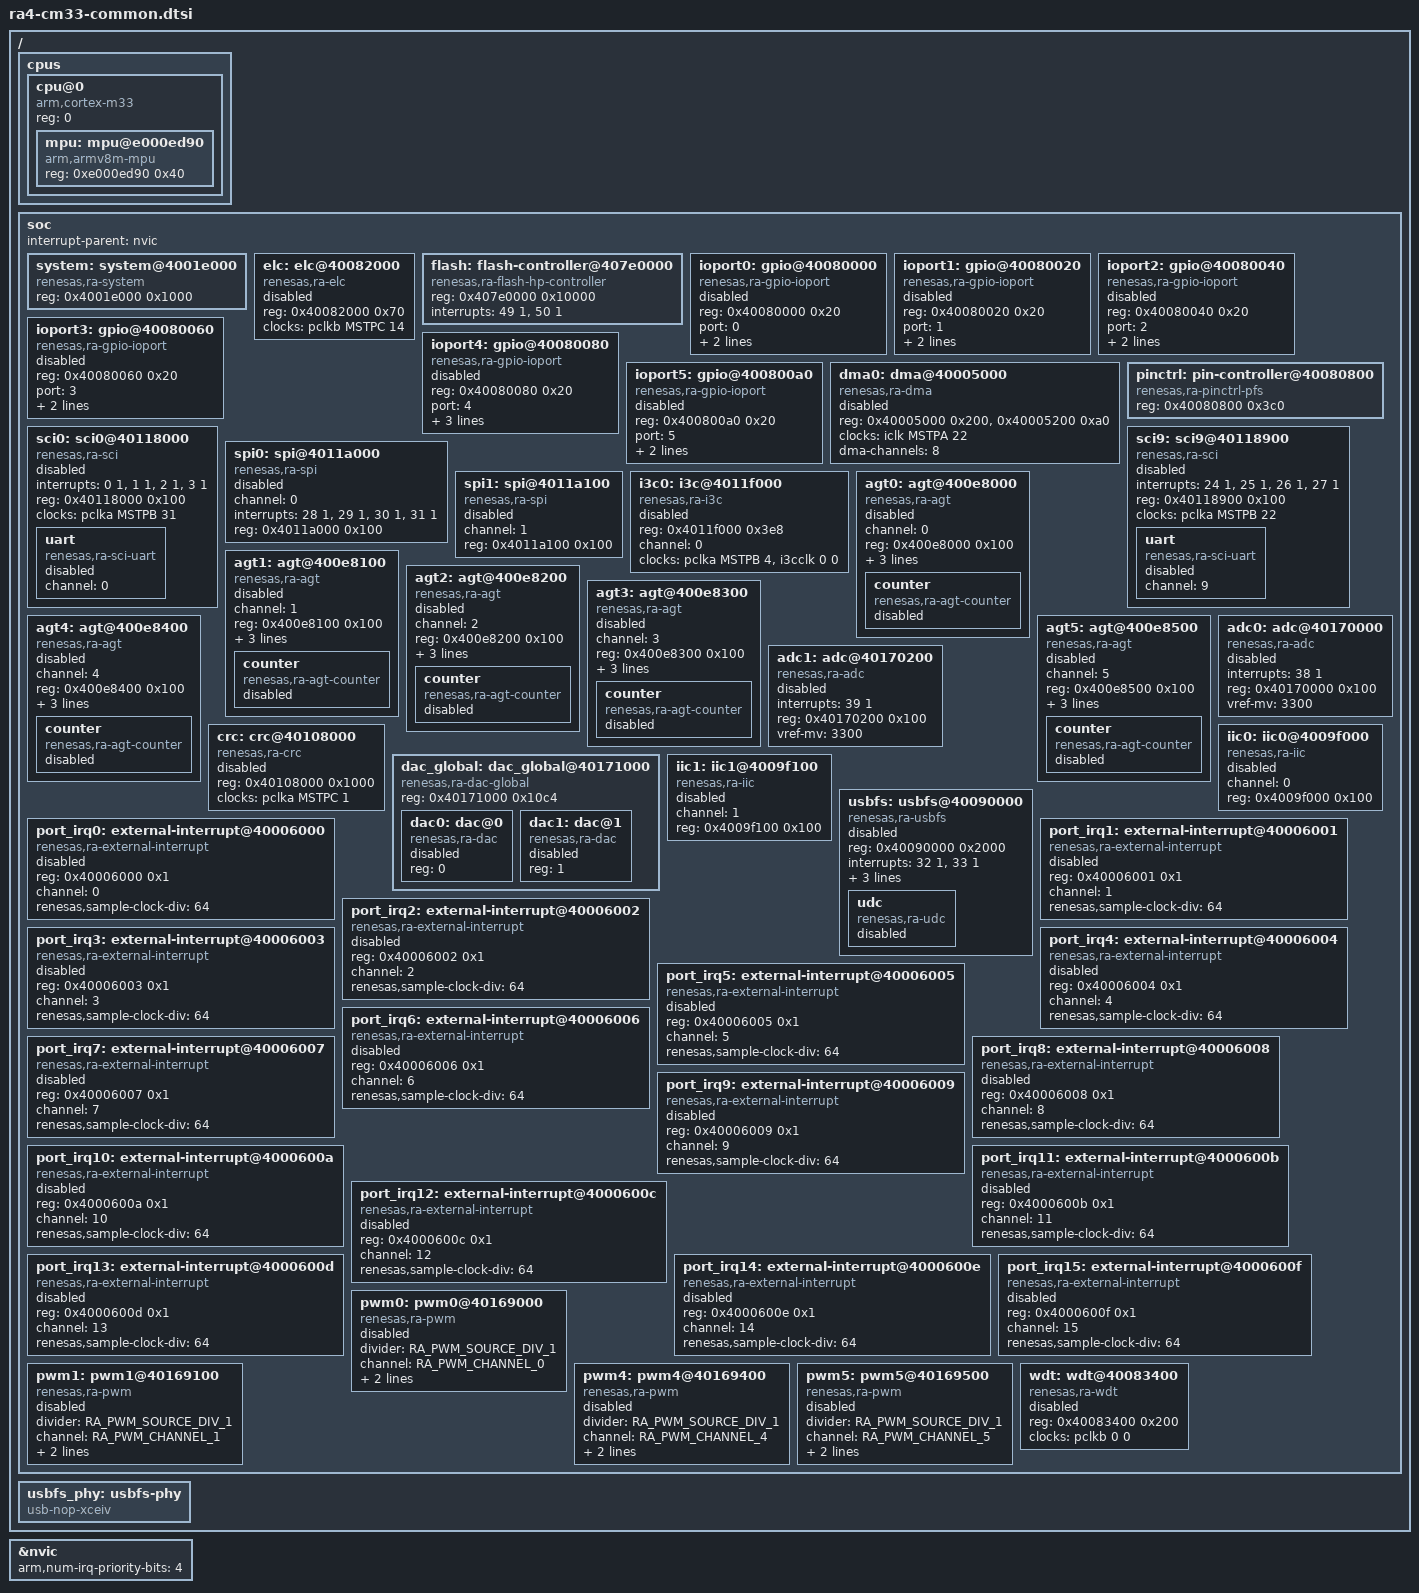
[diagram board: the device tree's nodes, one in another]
/*
 * Copyright (c) 2024-2025 Renesas Electronics Corporation
 *
 * SPDX-License-Identifier: Apache-2.0
 */

#include <mem.h>
#include <arm/armv8-m.dtsi>
#include <zephyr/dt-bindings/pinctrl/renesas/pinctrl-ra.h>
#include <zephyr/dt-bindings/pwm/ra_pwm.h>
#include <freq.h>

/ {
	cpus {
		#address-cells = <1>;
		#size-cells = <0>;

		cpu@0 {
			device_type = "cpu";
			compatible = "arm,cortex-m33";
			reg = <0>;
			#address-cells = <1>;
			#size-cells = <1>;

			mpu: mpu@e000ed90 {
				compatible = "arm,armv8m-mpu";
				reg = <0xe000ed90 0x40>;
			};
		};
	};

	soc {
		interrupt-parent = <&nvic>;

		system: system@4001e000 {
			compatible = "renesas,ra-system";
			reg = <0x4001e000 0x1000>;
			status = "okay";
		};

		elc: elc@40082000 {
			compatible = "renesas,ra-elc";
			reg = <0x40082000 0x70>;
			#renesas-elc-cells = <2>;
			clocks = <&pclkb MSTPC 14>;
			status = "disabled";
		};

		flash: flash-controller@407e0000 {
			compatible = "renesas,ra-flash-hp-controller";
			reg = <0x407e0000 0x10000>;
			#address-cells = <1>;
			#size-cells = <1>;
			interrupts = <49 1>, <50 1>;
			interrupt-names = "frdyi", "fiferr";
		};

		ioport0: gpio@40080000 {
			compatible = "renesas,ra-gpio-ioport";
			reg = <0x40080000 0x20>;
			port = <0>;
			gpio-controller;
			#gpio-cells = <2>;
			ngpios = <16>;
			status = "disabled";
		};

		ioport1: gpio@40080020 {
			compatible = "renesas,ra-gpio-ioport";
			reg = <0x40080020 0x20>;
			port = <1>;
			gpio-controller;
			#gpio-cells = <2>;
			ngpios = <16>;
			status = "disabled";
		};

		ioport2: gpio@40080040 {
			compatible = "renesas,ra-gpio-ioport";
			reg = <0x40080040 0x20>;
			port = <2>;
			gpio-controller;
			#gpio-cells = <2>;
			ngpios = <16>;
			status = "disabled";
		};

		ioport3: gpio@40080060 {
			compatible = "renesas,ra-gpio-ioport";
			reg = <0x40080060 0x20>;
			port = <3>;
			gpio-controller;
			#gpio-cells = <2>;
			ngpios = <16>;
			status = "disabled";
		};

		ioport4: gpio@40080080 {
			compatible = "renesas,ra-gpio-ioport";
			reg = <0x40080080 0x20>;
			port = <4>;
			gpio-controller;
			#gpio-cells = <2>;
			ngpios = <16>;
			vbatts-pins = <2 3 4>;
			status = "disabled";
		};

		ioport5: gpio@400800a0 {
			compatible = "renesas,ra-gpio-ioport";
			reg = <0x400800a0 0x20>;
			port = <5>;
			gpio-controller;
			#gpio-cells = <2>;
			ngpios = <16>;
			status = "disabled";
		};

		dma0: dma@40005000 {
			compatible = "renesas,ra-dma";
			reg = <0x40005000 0x200>, <0x40005200 0xa0>;
			reg-names = "channel", "common";
			clocks = <&iclk MSTPA 22>;
			dma-channels = <8>;
			#dma-cells = <2>;
			status = "disabled";
		};

		pinctrl: pin-controller@40080800 {
			compatible = "renesas,ra-pinctrl-pfs";
			reg = <0x40080800 0x3c0>;
			status = "okay";
		};

		sci0: sci0@40118000 {
			compatible = "renesas,ra-sci";
			interrupts = <0 1>, <1 1>, <2 1>, <3 1>;
			interrupt-names = "rxi", "txi", "tei", "eri";
			reg = <0x40118000 0x100>;
			clocks = <&pclka MSTPB 31>;
			status = "disabled";

			uart {
				compatible = "renesas,ra-sci-uart";
				channel = <0>;
				status = "disabled";
			};
		};

		sci9: sci9@40118900 {
			compatible = "renesas,ra-sci";
			interrupts = <24 1>, <25 1>, <26 1>, <27 1>;
			interrupt-names = "rxi", "txi", "tei", "eri";
			reg = <0x40118900 0x100>;
			clocks = <&pclka MSTPB 22>;
			status = "disabled";

			uart {
				compatible = "renesas,ra-sci-uart";
				channel = <9>;
				status = "disabled";
			};
		};

		spi0: spi@4011a000 {
			compatible = "renesas,ra-spi";
			#address-cells = <1>;
			#size-cells = <0>;
			channel = <0>;
			interrupts = <28 1>, <29 1>, <30 1>, <31 1>;
			interrupt-names = "rxi", "txi", "tei", "eri";
			reg = <0x4011a000 0x100>;
			status = "disabled";
		};

		spi1: spi@4011a100 {
			compatible = "renesas,ra-spi";
			#address-cells = <1>;
			#size-cells = <0>;
			channel = <1>;
			reg = <0x4011a100 0x100>;
			status = "disabled";
		};

		i3c0: i3c@4011f000 {
			compatible = "renesas,ra-i3c";
			#address-cells = <3>;
			#size-cells = <0>;
			reg = <0x4011f000 0x3e8>;
			channel = <0>;
			clocks = <&pclka MSTPB 4>, <&i3cclk 0 0>;
			clock-names = "pclk", "tclk";
			status = "disabled";
		};

		agt0: agt@400e8000 {
			compatible = "renesas,ra-agt";
			channel = <0>;
			reg = <0x400e8000 0x100>;
			renesas,count-source = "AGT_CLOCK_LOCO";
			renesas,prescaler = <0>;
			renesas,resolution = <16>;
			status = "disabled";

			counter {
				compatible = "renesas,ra-agt-counter";
				status = "disabled";
			};
		};

		agt1: agt@400e8100 {
			compatible = "renesas,ra-agt";
			channel = <1>;
			reg = <0x400e8100 0x100>;
			renesas,count-source = "AGT_CLOCK_LOCO";
			renesas,prescaler = <0>;
			renesas,resolution = <16>;
			status = "disabled";

			counter {
				compatible = "renesas,ra-agt-counter";
				status = "disabled";
			};
		};

		agt2: agt@400e8200 {
			compatible = "renesas,ra-agt";
			channel = <2>;
			reg = <0x400e8200 0x100>;
			renesas,count-source = "AGT_CLOCK_LOCO";
			renesas,prescaler = <0>;
			renesas,resolution = <16>;
			status = "disabled";

			counter {
				compatible = "renesas,ra-agt-counter";
				status = "disabled";
			};
		};

		agt3: agt@400e8300 {
			compatible = "renesas,ra-agt";
			channel = <3>;
			reg = <0x400e8300 0x100>;
			renesas,count-source = "AGT_CLOCK_LOCO";
			renesas,prescaler = <0>;
			renesas,resolution = <16>;
			status = "disabled";

			counter {
				compatible = "renesas,ra-agt-counter";
				status = "disabled";
			};
		};

		agt4: agt@400e8400 {
			compatible = "renesas,ra-agt";
			channel = <4>;
			reg = <0x400e8400 0x100>;
			renesas,count-source = "AGT_CLOCK_LOCO";
			renesas,prescaler = <0>;
			renesas,resolution = <16>;
			status = "disabled";

			counter {
				compatible = "renesas,ra-agt-counter";
				status = "disabled";
			};
		};

		agt5: agt@400e8500 {
			compatible = "renesas,ra-agt";
			channel = <5>;
			reg = <0x400e8500 0x100>;
			renesas,count-source = "AGT_CLOCK_LOCO";
			renesas,prescaler = <0>;
			renesas,resolution = <16>;
			status = "disabled";

			counter {
				compatible = "renesas,ra-agt-counter";
				status = "disabled";
			};
		};

		adc0: adc@40170000 {
			compatible = "renesas,ra-adc";
			interrupts = <38 1>;
			interrupt-names = "scanend";
			reg = <0x40170000 0x100>;
			#io-channel-cells = <1>;
			vref-mv = <3300>;
			status = "disabled";
		};

		adc1: adc@40170200 {
			compatible = "renesas,ra-adc";
			interrupts = <39 1>;
			interrupt-names = "scanend";
			reg = <0x40170200 0x100>;
			#io-channel-cells = <1>;
			vref-mv = <3300>;
			status = "disabled";
		};

		crc: crc@40108000 {
			compatible = "renesas,ra-crc";
			reg = <0x40108000 0x1000>;
			clocks = <&pclka MSTPC 1>;
			status = "disabled";
		};

		dac_global: dac_global@40171000 {
			compatible = "renesas,ra-dac-global";
			reg = <0x40171000 0x10c4>;
			#address-cells = <1>;
			#size-cells = <0>;

			dac0: dac@0 {
				compatible = "renesas,ra-dac";
				#io-channel-cells = <1>;
				reg = <0>;
				status = "disabled";
			};

			dac1: dac@1 {
				compatible = "renesas,ra-dac";
				#io-channel-cells = <1>;
				reg = <1>;
				status = "disabled";
			};
		};

		iic0: iic0@4009f000 {
			compatible = "renesas,ra-iic";
			channel = <0>;
			reg = <0x4009f000 0x100>;
			status = "disabled";
		};

		iic1: iic1@4009f100 {
			compatible = "renesas,ra-iic";
			channel = <1>;
			reg = <0x4009f100 0x100>;
			status = "disabled";
		};

		usbfs: usbfs@40090000 {
			compatible = "renesas,ra-usbfs";
			reg = <0x40090000 0x2000>;
			interrupts = <32 1>, <33 1>;
			interrupt-names = "usbfs-i", "usbfs-r";
			num-bidir-endpoints = <10>;
			phys = <&usbfs_phy>;
			phys-clock = <&uclk>;
			status = "disabled";

			udc {
				compatible = "renesas,ra-udc";
				status = "disabled";
			};
		};

		port_irq0: external-interrupt@40006000 {
			compatible = "renesas,ra-external-interrupt";
			reg = <0x40006000 0x1>;
			channel = <0>;
			renesas,sample-clock-div = <64>;
			#port-irq-cells = <0>;
			status = "disabled";
		};

		port_irq1: external-interrupt@40006001 {
			compatible = "renesas,ra-external-interrupt";
			reg = <0x40006001 0x1>;
			channel = <1>;
			renesas,sample-clock-div = <64>;
			#port-irq-cells = <0>;
			status = "disabled";
		};

		port_irq2: external-interrupt@40006002 {
			compatible = "renesas,ra-external-interrupt";
			reg = <0x40006002 0x1>;
			channel = <2>;
			renesas,sample-clock-div = <64>;
			#port-irq-cells = <0>;
			status = "disabled";
		};

		port_irq3: external-interrupt@40006003 {
			compatible = "renesas,ra-external-interrupt";
			reg = <0x40006003 0x1>;
			channel = <3>;
			renesas,sample-clock-div = <64>;
			#port-irq-cells = <0>;
			status = "disabled";
		};

		port_irq4: external-interrupt@40006004 {
			compatible = "renesas,ra-external-interrupt";
			reg = <0x40006004 0x1>;
			channel = <4>;
			renesas,sample-clock-div = <64>;
			#port-irq-cells = <0>;
			status = "disabled";
		};

		port_irq5: external-interrupt@40006005 {
			compatible = "renesas,ra-external-interrupt";
			reg = <0x40006005 0x1>;
			channel = <5>;
			renesas,sample-clock-div = <64>;
			#port-irq-cells = <0>;
			status = "disabled";
		};

		port_irq6: external-interrupt@40006006 {
			compatible = "renesas,ra-external-interrupt";
			reg = <0x40006006 0x1>;
			channel = <6>;
			renesas,sample-clock-div = <64>;
			#port-irq-cells = <0>;
			status = "disabled";
		};

		port_irq7: external-interrupt@40006007 {
			compatible = "renesas,ra-external-interrupt";
			reg = <0x40006007 0x1>;
			channel = <7>;
			renesas,sample-clock-div = <64>;
			#port-irq-cells = <0>;
			status = "disabled";
		};

		port_irq8: external-interrupt@40006008 {
			compatible = "renesas,ra-external-interrupt";
			reg = <0x40006008 0x1>;
			channel = <8>;
			renesas,sample-clock-div = <64>;
			#port-irq-cells = <0>;
			status = "disabled";
		};

		port_irq9: external-interrupt@40006009 {
			compatible = "renesas,ra-external-interrupt";
			reg = <0x40006009 0x1>;
			channel = <9>;
			renesas,sample-clock-div = <64>;
			#port-irq-cells = <0>;
			status = "disabled";
		};

		port_irq10: external-interrupt@4000600a {
			compatible = "renesas,ra-external-interrupt";
			reg = <0x4000600a 0x1>;
			channel = <10>;
			renesas,sample-clock-div = <64>;
			#port-irq-cells = <0>;
			status = "disabled";
		};

		port_irq11: external-interrupt@4000600b {
			compatible = "renesas,ra-external-interrupt";
			reg = <0x4000600b 0x1>;
			channel = <11>;
			renesas,sample-clock-div = <64>;
			#port-irq-cells = <0>;
			status = "disabled";
		};

		port_irq12: external-interrupt@4000600c {
			compatible = "renesas,ra-external-interrupt";
			reg = <0x4000600c 0x1>;
			channel = <12>;
			renesas,sample-clock-div = <64>;
			#port-irq-cells = <0>;
			status = "disabled";
		};

		port_irq13: external-interrupt@4000600d {
			compatible = "renesas,ra-external-interrupt";
			reg = <0x4000600d 0x1>;
			channel = <13>;
			renesas,sample-clock-div = <64>;
			#port-irq-cells = <0>;
			status = "disabled";
		};

		port_irq14: external-interrupt@4000600e {
			compatible = "renesas,ra-external-interrupt";
			reg = <0x4000600e 0x1>;
			channel = <14>;
			renesas,sample-clock-div = <64>;
			#port-irq-cells = <0>;
			status = "disabled";
		};

		port_irq15: external-interrupt@4000600f {
			compatible = "renesas,ra-external-interrupt";
			reg = <0x4000600f 0x1>;
			channel = <15>;
			renesas,sample-clock-div = <64>;
			#port-irq-cells = <0>;
			status = "disabled";
		};

		pwm0: pwm0@40169000 {
			compatible = "renesas,ra-pwm";
			divider = <RA_PWM_SOURCE_DIV_1>;
			channel = <RA_PWM_CHANNEL_0>;
			clocks = <&pclkd MSTPE 31>;
			reg = <0x40169000 0x100>;
			#pwm-cells = <3>;
			status = "disabled";
		};

		pwm1: pwm1@40169100 {
			compatible = "renesas,ra-pwm";
			divider = <RA_PWM_SOURCE_DIV_1>;
			channel = <RA_PWM_CHANNEL_1>;
			clocks = <&pclkd MSTPE 30>;
			reg = <0x40169100 0x100>;
			#pwm-cells = <3>;
			status = "disabled";
		};

		pwm4: pwm4@40169400 {
			compatible = "renesas,ra-pwm";
			divider = <RA_PWM_SOURCE_DIV_1>;
			channel = <RA_PWM_CHANNEL_4>;
			clocks = <&pclkd MSTPE 27>;
			reg = <0x40169400 0x100>;
			#pwm-cells = <3>;
			status = "disabled";
		};

		pwm5: pwm5@40169500 {
			compatible = "renesas,ra-pwm";
			divider = <RA_PWM_SOURCE_DIV_1>;
			channel = <RA_PWM_CHANNEL_5>;
			clocks = <&pclkd MSTPE 26>;
			reg = <0x40169500 0x100>;
			#pwm-cells = <3>;
			status = "disabled";
		};

		wdt: wdt@40083400 {
			compatible = "renesas,ra-wdt";
			reg = <0x40083400 0x200>;
			clocks = <&pclkb 0 0>;
			status = "disabled";
		};
	};

	usbfs_phy: usbfs-phy {
		compatible = "usb-nop-xceiv";
		#phy-cells = <0>;
	};
};

&nvic {
	arm,num-irq-priority-bits = <4>;
};
